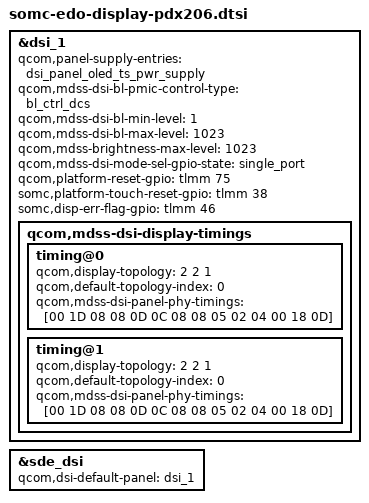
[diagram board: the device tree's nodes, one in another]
/* Copyright (c) 2015-2020, The Linux Foundation. All rights reserved.
 *
 * This program is free software; you can redistribute it and/or modify
 * it under the terms of the GNU General Public License version 2 and
 * only version 2 as published by the Free Software Foundation.
 *
 * This program is distributed in the hope that it will be useful,
 * but WITHOUT ANY WARRANTY; without even the implied warranty of
 * MERCHANTABILITY or FITNESS FOR A PARTICULAR PURPOSE.  See the
 * GNU General Public License for more details.
 */
#include "dsi-panel-sofef03_m-fhd_plus.dtsi"

&dsi_1 {
	qcom,panel-supply-entries = <&dsi_panel_oled_ts_pwr_supply>;
	qcom,mdss-dsi-bl-pmic-control-type = "bl_ctrl_dcs";
	qcom,mdss-dsi-bl-min-level = <1>;
	qcom,mdss-dsi-bl-max-level = <1023>;
	qcom,mdss-brightness-max-level = <1023>;
	qcom,mdss-dsi-mode-sel-gpio-state = "single_port";

	qcom,platform-reset-gpio = <&tlmm 75 0>;
	somc,platform-touch-reset-gpio = <&tlmm 38 0>;
	somc,disp-err-flag-gpio = <&tlmm 46 0>;

	qcom,mdss-dsi-display-timings {
		timing@0 {
			qcom,display-topology = <2 2 1>;
			qcom,default-topology-index = <0>;
			qcom,mdss-dsi-panel-phy-timings = [00 1D 08 08 0D 0C 08 08 05 02 04 00 18 0D];
		};
		timing@1 {
			qcom,display-topology = <2 2 1>;
			qcom,default-topology-index = <0>;
			qcom,mdss-dsi-panel-phy-timings = [00 1D 08 08 0D 0C 08 08 05 02 04 00 18 0D];
		};
	};
};

&sde_dsi {
	qcom,dsi-default-panel = <&dsi_1>;
};
